# STM32H5E5 register map
File version: 1.0
CPU: CM33 r0p0, little endian, MPU, FPU, 4 interrupt priority bits
Registers are 32-bit, read-write, reset 0x0 unless marked. A register's access mark holds for its fields unless they carry their own. Offsets are from the block's base; [hi:lo] are bit positions; {n}, {i} and the like mark numbered series.

## GTZC1_TZIC — GTZC1_MPCBBz register block
Base 0x40032800
Same registers: GTZC1_TZIC_S 0x50032800
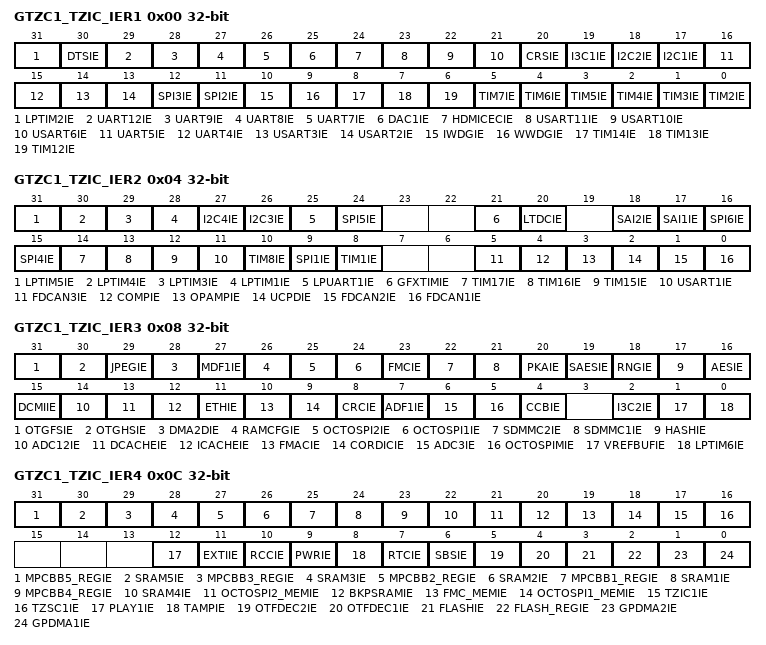
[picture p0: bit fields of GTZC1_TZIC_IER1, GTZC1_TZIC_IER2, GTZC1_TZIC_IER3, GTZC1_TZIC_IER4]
0x00 GTZC1_TZIC_IER1 (alternate view of GTZC1_TZSC_CR) — GTZC1 TZIC interrupt enable register 1
  [all] fields
    0=interrupt disabled; 1=interrupt enabled
  [31] LPTIM2IE — illegal access interrupt enable for LPTIM2
  [30] DTSIE — illegal access interrupt enable for DTS
  [29] UART12IE — illegal access interrupt enable for UART12
  [28] UART9IE — illegal access interrupt enable for UART9
  [27] UART8IE — illegal access interrupt enable for UART8
  [26] UART7IE — illegal access interrupt enable for UART7
  [25] DAC1IE — illegal access interrupt enable for DAC1
  [24] HDMICECIE — illegal access interrupt enable for HDMICEC
  [23] USART11IE — illegal access interrupt enable for USART11
  [22] USART10IE — illegal access interrupt enable for USART10
  [21] USART6IE — illegal access interrupt enable for USART6
  [20] CRSIE — illegal access interrupt enable for CRS
  [19] I3C1IE — illegal access interrupt enable for I3C1
  [18] I2C2IE — illegal access interrupt enable for I2C2
  [17] I2C1IE — illegal access interrupt enable for I2C1
  [16] UART5IE — illegal access interrupt enable for UART5
  [15] UART4IE — illegal access interrupt enable for UART4
  [14] USART3IE — illegal access interrupt enable for USART3
  [13] USART2IE — illegal access interrupt enable for USART2
  [12] SPI3IE — illegal access interrupt enable for SPI3
  [11] SPI2IE — illegal access interrupt enable for SPI2
  [10] IWDGIE — illegal access interrupt enable for IWDG
  [9] WWDGIE — illegal access interrupt enable for WWDG
  [8] TIM14IE — illegal access interrupt enable for TIM14
  [7] TIM13IE — illegal access interrupt enable for TIM13
  [6] TIM12IE — illegal access interrupt enable for TIM12
  [n-2] TIM{n}IE (n=2..7) — illegal access interrupt enable for TIM{n}
0x04 GTZC1_TZIC_IER2 — GTZC1 TZIC interrupt enable register 2
  [all] fields
    0=interrupt disabled; 1=interrupt enabled
  [31] LPTIM5IE — illegal access interrupt enable for LPTIM5
  [30] LPTIM4IE — illegal access interrupt enable for LPTIM4
  [29] LPTIM3IE — illegal access interrupt enable for LPTIM3
  [28] LPTIM1IE — illegal access interrupt enable for LPTIM1
  [27] I2C4IE — illegal access interrupt enable for I2C4
  [26] I2C3IE — illegal access interrupt enable for I2C3
  [25] LPUART1IE — illegal access interrupt enable for LPUART
  [24] SPI5IE — illegal access interrupt enable for SPI5
  [21] GFXTIMIE — illegal access interrupt enable for GFXTIM
  [20] LTDCIE — illegal access interrupt enable for LTDC
  [18] SAI2IE — illegal access interrupt enable for SAI2
  [17] SAI1IE — illegal access interrupt enable for SAI1
  [16] SPI6IE — illegal access interrupt enable for SPI6
  [15] SPI4IE — illegal access interrupt enable for SPI4
  [14] TIM17IE — illegal access interrupt enable for TIM17
  [13] TIM16IE — illegal access interrupt enable for TIM16
  [12] TIM15IE — illegal access interrupt enable for TIM15
  [11] USART1IE — illegal access interrupt enable for USART1
  [10] TIM8IE — illegal access interrupt enable for TIM8
  [9] SPI1IE — illegal access interrupt enable for SPI1
  [8] TIM1IE — illegal access interrupt enable for TIM1
  [5] FDCAN3IE — illegal access interrupt enable for FDCAN3
  [4] COMPIE — illegal access interrupt enable for COMP
  [3] OPAMPIE — illegal access interrupt enable for OPAMP
  [2] UCPDIE — illegal access interrupt enable for UCPD
  [1] FDCAN2IE — illegal access interrupt enable for FDCAN2
  [0] FDCAN1IE — illegal access interrupt enable for FDCAN1
0x08 GTZC1_TZIC_IER3 — GTZC1 TZIC interrupt enable register 3
  [all] fields
    0=interrupt disabled; 1=interrupt enabled
  [31] OTGFSIE — illegal access interrupt enable for OTGFS
  [30] OTGHSIE — illegal access interrupt enable for OTGHS
  [29] JPEGIE — illegal access interrupt enable for JPEG
  [28] DMA2DIE — illegal access interrupt enable for DMA2D
  [27] MDF1IE — illegal access interrupt enable for MDF1
  [26] RAMCFGIE — illegal access interrupt enable for RAMSCFG
  [25] OCTOSPI2IE — illegal access interrupt enable for OCTOSPI2
  [24] OCTOSPI1IE — illegal access interrupt enable for OCTOSPI1
  [23] FMCIE — illegal access interrupt enable for FMC
  [22] SDMMC2IE — illegal access interrupt enable for SDMMC2
  [21] SDMMC1IE — illegal access interrupt enable for SDMMC1
  [20] PKAIE — illegal access interrupt enable for PKA
  [19] SAESIE — illegal access interrupt enable for SAES
  [18] RNGIE — illegal access interrupt enable for RNG
  [17] HASHIE — illegal access interrupt enable for HASH
  [16] AESIE — illegal access interrupt enable for AES
  [15] DCMIIE — illegal access interrupt enable for DCMI
  [14] ADC12IE — illegal access interrupt enable for ADC1 and ADC2
  [13] DCACHEIE — illegal access interrupt enable for DCACHE
  [12] ICACHEIE — illegal access interrupt enable for ICACHE
  [11] ETHIE — illegal access interrupt enable for register of ETH
  [10] FMACIE — illegal access interrupt enable for FMAC
  [9] CORDICIE — illegal access interrupt enable for CORDIC
  [8] CRCIE — illegal access interrupt enable for CRC
  [7] ADF1IE — illegal access interrupt enable for ADF1
  [6] ADC3IE — illegal access interrupt enable for ADC3
  [5] OCTOSPIMIE — illegal access interrupt enable for OCTOSPIM
  [4] CCBIE — illegal access interrupt enable for CCB
  [2] I3C2IE — illegal access interrupt enable for I3C2
  [1] VREFBUFIE — illegal access interrupt enable for VREFBUF
  [0] LPTIM6IE — illegal access interrupt enable for LPTIM6
0x0C GTZC1_TZIC_IER4 — GTZC1 TZIC interrupt enable register 4
  [all] fields
    0=interrupt disabled; 1=interrupt enabled
  [31] MPCBB5_REGIE — illegal access interrupt enable for MPCBB5 registers
  [30] SRAM5IE — illegal access interrupt enable for SRAM5
  [29] MPCBB3_REGIE — illegal access interrupt enable for MPCBB3 registers
  [28] SRAM3IE — illegal access interrupt enable for SRAM3
  [27] MPCBB2_REGIE — illegal access interrupt enable for MPCBB2 registers
  [26] SRAM2IE — illegal access interrupt enable for SRAM2
  [25] MPCBB1_REGIE — illegal access interrupt enable for MPCBB1 registers
  [24] SRAM1IE — illegal access interrupt enable for SRAM1
  [23] MPCBB4_REGIE — illegal access interrupt enable for MPCBB4 registers
  [22] SRAM4IE — illegal access interrupt enable for SRAM4
  [21] OCTOSPI2_MEMIE — illegal access interrupt enable for MPCWM5 (OCTOSPI2) memory bank
  [20] BKPSRAMIE — illegal access interrupt enable for MPCWM4 (BKPSRAM) memory bank
  [19] FMC_MEMIE — illegal access interrupt enable for MPCWM2 (FMC_NOR bank), MPCWM3 (FMC_NAND bank and FMC_SDRAM bank 1), and MPCWM4 (FMC_SDRAMbank 2)
  [18] OCTOSPI1_MEMIE — illegal access interrupt enable for MPCWM1 (OCTOSPI1) memory bank
  [17] TZIC1IE — illegal access interrupt enable for GTZC1 TZIC registers
  [16] TZSC1IE — illegal access interrupt enable for GTZC1 TZSC registers
  [12] PLAY1IE — illegal access interrupt enable for PLAY1
  [11] EXTIIE — illegal access interrupt enable for EXTI
  [10] RCCIE — illegal access interrupt enable for RCC
  [9] PWRIE — illegal access interrupt enable for PWR
  [8] TAMPIE — illegal access interrupt enable for TAMP
  [7] RTCIE — illegal access interrupt enable for RTC
  [6] SBSIE — illegal access interrupt enable for SBS
  [5] OTFDEC2IE — illegal access interrupt enable for OTFDEC2
  [4] OTFDEC1IE — illegal access interrupt enable for OTFDEC1
  [3] FLASHIE — illegal access interrupt enable for FLASH memory
  [2] FLASH_REGIE — illegal access interrupt enable for FLASH registers
  [1] GPDMA2IE — illegal access interrupt enable for GPDMA2
  [0] GPDMA1IE — illegal access interrupt enable for GPDMA1
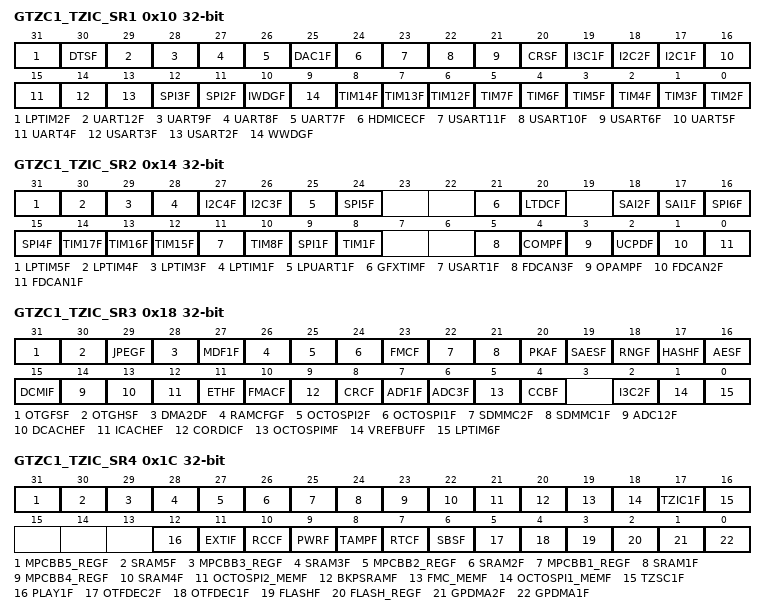
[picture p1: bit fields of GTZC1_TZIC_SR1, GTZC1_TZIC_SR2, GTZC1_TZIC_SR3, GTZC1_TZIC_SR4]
0x10 GTZC1_TZIC_SR1 ro (alternate view of GTZC1_TZSC_SECCFGR1) — GTZC1 TZIC status register 1
  [all] fields
    0=no illegal access event; 1=illegal access event
  [31] LPTIM2F — illegal access flag for LPTIM2
  [30] DTSF — illegal access flag for DTS
  [29] UART12F — illegal access flag for UART12
  [28] UART9F — illegal access flag for UART9
  [27] UART8F — illegal access flag for UART8
  [26] UART7F — illegal access flag for UART7
  [25] DAC1F — illegal access flag for DAC1
  [24] HDMICECF — illegal access flag for HDMICEC
  [23] USART11F — illegal access flag for USART11
  [22] USART10F — illegal access flag for USART10
  [21] USART6F — illegal access flag for USART6
  [20] CRSF — illegal access flag for CRS
  [19] I3C1F — illegal access flag for I3C1
  [18] I2C2F — illegal access flag for I2C2
  [17] I2C1F — illegal access flag for I2C1
  [16] UART5F — illegal access flag for UART5
  [15] UART4F — illegal access flag for UART4
  [14] USART3F — illegal access flag for USART3
  [13] USART2F — illegal access flag for USART2
  [12] SPI3F — illegal access flag for SPI3
  [11] SPI2F — illegal access flag for SPI2
  [10] IWDGF — illegal access flag for IWDG
  [9] WWDGF — illegal access flag for WWDG
  [8] TIM14F — illegal access flag for TIM14
  [7] TIM13F — illegal access flag for TIM13
  [6] TIM12F — illegal access flag for TIM12
  [n-2] TIM{n}F (n=2..7) — illegal access flag for TIM{n}
0x14 GTZC1_TZIC_SR2 ro (alternate view of GTZC1_TZSC_SECCFGR2) — GTZC1 TZIC status register 2
  [all] fields
    0=no illegal access event; 1=illegal access event
  [31] LPTIM5F — illegal access flag for LPTIM5
  [30] LPTIM4F — illegal access flag for LPTIM4
  [29] LPTIM3F — illegal access flag for LPTIM3
  [28] LPTIM1F — illegal access flag for LPTIM1
  [27] I2C4F — illegal access flag for I2C4
  [26] I2C3F — illegal access flag for I2C3
  [25] LPUART1F — illegal access flag for LPUART
  [24] SPI5F — illegal access flag for SPI5
  [21] GFXTIMF — illegal access flag for GFXTIM
  [20] LTDCF — illegal access flag for LTDC
  [18] SAI2F — illegal access flag for SAI2
  [17] SAI1F — illegal access flag for SAI1
  [16] SPI6F — illegal access flag for SPI6
  [15] SPI4F — illegal access flag for SPI4
  [14] TIM17F — illegal access flag for TIM17
  [13] TIM16F — illegal access flag for TIM16
  [12] TIM15F — illegal access flag for TIM15
  [11] USART1F — illegal access flag for USART1
  [10] TIM8F — illegal access flag for TIM8
  [9] SPI1F — illegal access flag for SPI1
  [8] TIM1F — illegal access flag for TIM1
  [5] FDCAN3F — illegal access flag for FDCAN3
  [4] COMPF — illegal access flag for COMP
  [3] OPAMPF — illegal access flag for OPAMP
  [2] UCPDF — illegal access flag for UCPD
  [1] FDCAN2F — illegal access flag for FDCAN2
  [0] FDCAN1F — illegal access flag for FDCAN1
0x18 GTZC1_TZIC_SR3 ro (alternate view of GTZC1_TZSC_SECCFGR3) — GTZC1 TZIC status register 3
  [all] fields
    0=no illegal access event; 1=illegal access event
  [31] OTGFSF — illegal access flag for OTGFSF
  [30] OTGHSF — illegal access flag for OTGHSF
  [29] JPEGF — illegal access flag for JPEGF
  [28] DMA2DF — illegal access flag for DMA2D
  [27] MDF1F — illegal access flag for MDF1
  [26] RAMCFGF — illegal access flag for RAMSCFG
  [25] OCTOSPI2F — illegal access flag for OCTOSPI2
  [24] OCTOSPI1F — illegal access flag for OCTOSPI1
  [23] FMCF — illegal access flag for FMC
  [22] SDMMC2F — illegal access flag for SDMMC2
  [21] SDMMC1F — illegal access flag for SDMMC1
  [20] PKAF — illegal access flag for PKA
  [19] SAESF — illegal access flag for SAES
  [18] RNGF — illegal access flag for RNG
  [17] HASHF — illegal access flag for HASH
  [16] AESF — illegal access flag for AES
  [15] DCMIF — illegal access flag for DCMI
  [14] ADC12F — illegal access flag for ADC1 and ADC2
  [13] DCACHEF — illegal access flag for DCACHE
  [12] ICACHEF — illegal access flag for ICACHE
  [11] ETHF — illegal access flag for register of ETH
  [10] FMACF — illegal access flag for FMAC
  [9] CORDICF — illegal access flag for CORDIC
  [8] CRCF — illegal access flag for CRC
  [7] ADF1F — illegal access flag for ADF1
  [6] ADC3F — illegal access flag for ADC3
  [5] OCTOSPIMF — illegal access flag for OCTOSPIM
  [4] CCBF — illegal access flag for CCB
  [2] I3C2F — illegal access flag for I3C2
  [1] VREFBUFF — illegal access flag for VREFBUF
  [0] LPTIM6F — illegal access flag for LPTIM6
0x1C GTZC1_TZIC_SR4 ro — GTZC1 TZIC status register 4
  [all] fields
    0=no illegal access event; 1=illegal access event
  [31] MPCBB5_REGF — illegal access flag for MPCBB5 registers
  [30] SRAM5F — illegal access flag for SRAM5
  [29] MPCBB3_REGF — illegal access flag for MPCBB3 registers
  [28] SRAM3F — illegal access flag for SRAM3
  [27] MPCBB2_REGF — illegal access flag for MPCBB2 registers
  [26] SRAM2F — illegal access flag for SRAM2
  [25] MPCBB1_REGF — illegal access flag for MPCBB1 registers
  [24] SRAM1F — illegal access flag for SRAM1
  [23] MPCBB4_REGF — illegal access flag for MPCBB4 registers
  [22] SRAM4F — illegal access flag for SRAM4
  [21] OCTOSPI2_MEMF — illegal access flag for MPCWM5 (OCTOSPI2) memory bank
  [20] BKPSRAMF — illegal access flag for MPCWM4 (BKPSRAM) memory bank
  [19] FMC_MEMF — illegal access flag for MPCWM2 (FMC_NOR bank), MPCWM3 (FMC_NAND bank and FMC_SDRAM bank 1), and MPCWM4 (FMC_SDRAMbank 2)
  [18] OCTOSPI1_MEMF — illegal access flag for MPCWM1 (OCTOSPI1) memory bank
  [17] TZIC1F — illegal access flag for GTZC1 TZIC registers
  [16] TZSC1F — illegal access flag for GTZC1 TZSC registers
  [12] PLAY1F — illegal access flag for PLAY1
  [11] EXTIF — illegal access flag for EXTI
  [10] RCCF — illegal access flag for RCC
  [9] PWRF — illegal access flag for PWR
  [8] TAMPF — illegal access flag for TAMP
  [7] RTCF — illegal access flag for RTC
  [6] SBSF — illegal access flag for SBS
  [5] OTFDEC2F — illegal access flag for OTFDEC2
  [4] OTFDEC1F — illegal access flag for OTFDEC1
  [3] FLASHF — illegal access flag for FLASH memory
  [2] FLASH_REGF — illegal access flag for FLASH registers
  [1] GPDMA2F — illegal access flag for GPDMA2
  [0] GPDMA1F — illegal access flag for GPDMA1
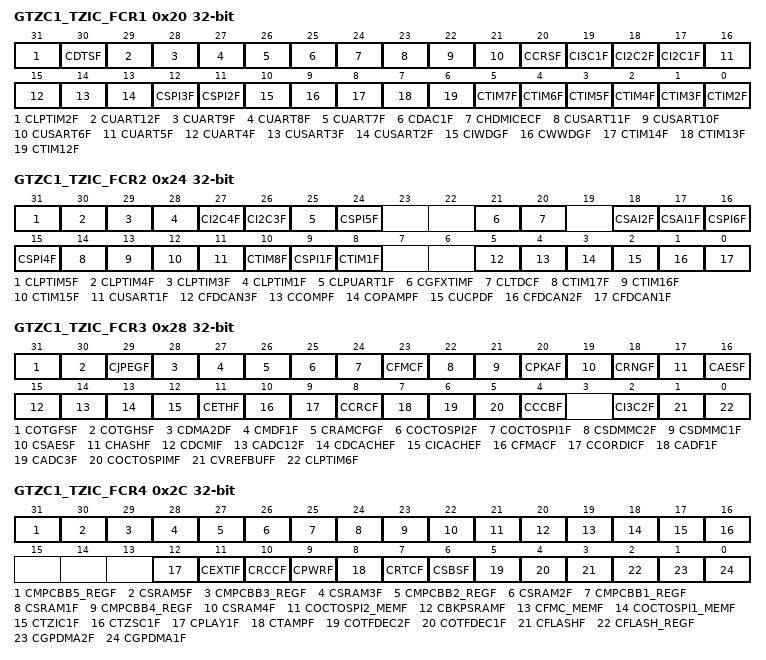
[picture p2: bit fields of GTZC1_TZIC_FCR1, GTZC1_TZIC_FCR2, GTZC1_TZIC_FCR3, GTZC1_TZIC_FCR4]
0x20 GTZC1_TZIC_FCR1 wo (alternate view of GTZC1_TZSC_PRIVCFGR1) — GTZC1 TZIC flag clear register 1
  [all] fields
    0=no action; 1=status flag cleared
  [31] CLPTIM2F — clear the illegal access flag for LPTIM2
  [30] CDTSF — clear the illegal access flag for DTS
  [29] CUART12F — clear the illegal access flag for UART12
  [28] CUART9F — clear the illegal access flag for UART9
  [27] CUART8F — clear the illegal access flag for UART8
  [26] CUART7F — clear the illegal access flag for UART7
  [25] CDAC1F — clear the illegal access flag for DAC1
  [24] CHDMICECF — clear the illegal access flag for HDMICEC
  [23] CUSART11F — clear the illegal access flag for USART11
  [22] CUSART10F — clear the illegal access flag for USART10
  [21] CUSART6F — clear the illegal access flag for USART6
  [20] CCRSF — clear the illegal access flag for CRS
  [19] CI3C1F — clear the illegal access flag for I3C1
  [18] CI2C2F — clear the illegal access flag for I2C2
  [17] CI2C1F — clear the illegal access flag for I2C1
  [16] CUART5F — clear the illegal access flag for UART5
  [15] CUART4F — clear the illegal access flag for UART4
  [14] CUSART3F — clear the illegal access flag for USART3
  [13] CUSART2F — clear the illegal access flag for USART2
  [12] CSPI3F — clear the illegal access flag for SPI3
  [11] CSPI2F — clear the illegal access flag for SPI2
  [10] CIWDGF — clear the illegal access flag for IWDG
  [9] CWWDGF — clear the illegal access flag for WWDG
  [8] CTIM14F — clear the illegal access flag for TIM14
  [7] CTIM13F — clear the illegal access flag for TIM13
  [6] CTIM12F — clear the illegal access flag for TIM12
  [n-2] CTIM{n}F (n=2..7) — clear the illegal access flag for TIM{n}
0x24 GTZC1_TZIC_FCR2 wo (alternate view of GTZC1_TZSC_PRIVCFGR2) — GTZC1 TZIC flag clear register 2
  [all] fields
    0=no action; 1=status flag cleared
  [31] CLPTIM5F — clear the illegal access flag for LPTIM5
  [30] CLPTIM4F — clear the illegal access flag for LPTIM4
  [29] CLPTIM3F — clear the illegal access flag for LPTIM3
  [28] CLPTIM1F — clear the illegal access flag for LPTIM1
  [27] CI2C4F — clear the illegal access flag for I2C4
  [26] CI2C3F — clear the illegal access flag for I2C3
  [25] CLPUART1F — clear the illegal access flag for LPUART
  [24] CSPI5F — clear the illegal access flag for SPI5
  [21] CGFXTIMF — clear the illegal access flag for GFXTIM
  [20] CLTDCF — clear the illegal access flag for LTDC
  [18] CSAI2F — clear the illegal access flag for SAI2
  [17] CSAI1F — clear the illegal access flag for SAI1
  [16] CSPI6F — clear the illegal access flag for SPI6
  [15] CSPI4F — clear the illegal access flag for SPI4
  [14] CTIM17F — clear the illegal access flag for TIM17
  [13] CTIM16F — clear the illegal access flag for TIM16
  [12] CTIM15F — clear the illegal access flag for TIM15
  [11] CUSART1F — clear the illegal access flag for USART1
  [10] CTIM8F — clear the illegal access flag for TIM8
  [9] CSPI1F — clear the illegal access flag for SPI1
  [8] CTIM1F — clear the illegal access flag for TIM1
  [5] CFDCAN3F — clear the illegal access flag for FDCAN3
  [4] CCOMPF — clear the illegal access flag for COMP
  [3] COPAMPF — clear the illegal access flag for OPAMP
  [2] CUCPDF — clear the illegal access flag for UCPD
  [1] CFDCAN2F — clear the illegal access flag for FDCAN2
  [0] CFDCAN1F — clear the illegal access flag for FDCAN1
0x28 GTZC1_TZIC_FCR3 wo (alternate view of GTZC1_TZSC_PRIVCFGR3) — GTZC1 TZIC flag clear register 3
  [all] fields
    0=no action; 1=status flag cleared
  [31] COTGFSF — clear illegal access flag for OTGFS
  [30] COTGHSF — clear illegal access flag for OTGHS
  [29] CJPEGF — clear illegal access flag for JPEG
  [28] CDMA2DF — clear illegal access flag for DMA2D
  [27] CMDF1F — clear illegal access flag for MDF1
  [26] CRAMCFGF — clear illegal access flag for RAMSCFG
  [25] COCTOSPI2F — clear illegal access flag for OCTOSPI2
  [24] COCTOSPI1F — clear illegal access flag for OCTOSPI1
  [23] CFMCF — clear illegal access flag for FMC
  [22] CSDMMC2F — clear illegal access flag for SDMMC2
  [21] CSDMMC1F — clear illegal access flag for SDMMC1
  [20] CPKAF — clear illegal access flag for PKA
  [19] CSAESF — clear illegal access flag for SAES
  [18] CRNGF — clear illegal access flag for RNG
  [17] CHASHF — clear illegal access flag for HASH
  [16] CAESF — clear illegal access flag for AES
  [15] CDCMIF — clear illegal access flag for DCMI
  [14] CADC12F — clear illegal access flag for ADC1 and ADC2
  [13] CDCACHEF — clear illegal access flag for DCACHE
  [12] CICACHEF — clear illegal access flag for ICACHE
  [11] CETHF — clear illegal access flag for register of ETH
  [10] CFMACF — clear illegal access flag for FMAC
  [9] CCORDICF — clear illegal access flag for CORDIC
  [8] CCRCF — clear illegal access flag for CRC
  [7] CADF1F — clear illegal access flag for ADF1
  [6] CADC3F — clear illegal access flag for ADC3
  [5] COCTOSPIMF — clear illegal access flag for OCTOSPIM
  [4] CCCBF — clear illegal access flag for CCB
  [2] CI3C2F — clear illegal access flag for I3C2
  [1] CVREFBUFF — clear illegal access flag for VREFBUF
  [0] CLPTIM6F — clear illegal access flag for LPTIM6
0x2C GTZC1_TZIC_FCR4 wo — GTZC1 TZIC flag clear register 4
  [all] fields
    0=no action; 1=status flag cleared
  [31] CMPCBB5_REGF — clear the illegal access flag for MPCBB5 registers
  [30] CSRAM5F — clear the illegal access flag for SRAM5
  [29] CMPCBB3_REGF — clear the illegal access flag for MPCBB3 registers
  [28] CSRAM3F — clear the illegal access flag for SRAM3
  [27] CMPCBB2_REGF — clear the illegal access flag for MPCBB2 registers
  [26] CSRAM2F — clear the illegal access flag for SRAM2
  [25] CMPCBB1_REGF — clear the illegal access flag for MPCBB1 registers
  [24] CSRAM1F — clear the illegal access flag for SRAM1
  [23] CMPCBB4_REGF — clear the illegal access flag for MPCBB4 registers
  [22] CSRAM4F — clear the illegal access flag for SRAM4
  [21] COCTOSPI2_MEMF — clear the illegal access flag for MPCWM5 (OCTOSPI2) memory bank
  [20] CBKPSRAMF — clear the illegal access flag for MPCWM4 (BKPSRAM) memory bank
  [19] CFMC_MEMF — clear the illegal access flag for MPCWM2 (FMC_NOR bank), MPCWM3 (FMC_NAND bank and FMC_SDRAM bank 1), and MPCWM4 (FMC_SDRAMbank 2)
  [18] COCTOSPI1_MEMF — clear the illegal access flag for MPCWM1 (OCTOSPI1) memory bank
  [17] CTZIC1F — clear the illegal access flag for GTZC1 TZIC registers
  [16] CTZSC1F — clear the illegal access flag for GTZC1 TZSC registers
  [12] CPLAY1F — clear the illegal access flag for PLAY1
  [11] CEXTIF — clear the illegal access flag for EXTI
  [10] CRCCF — clear the illegal access flag for RCC
  [9] CPWRF — clear the illegal access flag for PWR
  [8] CTAMPF — clear the illegal access flag for TAMP
  [7] CRTCF — clear the illegal access flag for RTC
  [6] CSBSF — clear the illegal access flag for SBS
  [5] COTFDEC2F — clear the illegal access flag for OTFDEC2
  [4] COTFDEC1F — clear the illegal access flag for OTFDEC1
  [3] CFLASHF — clear the illegal access flag for FLASH memory
  [2] CFLASH_REGF — clear the illegal access flag for FLASH registers
  [1] CGPDMA2F — clear the illegal access flag for GPDMA2
  [0] CGPDMA1F — clear the illegal access flag for GPDMA1
